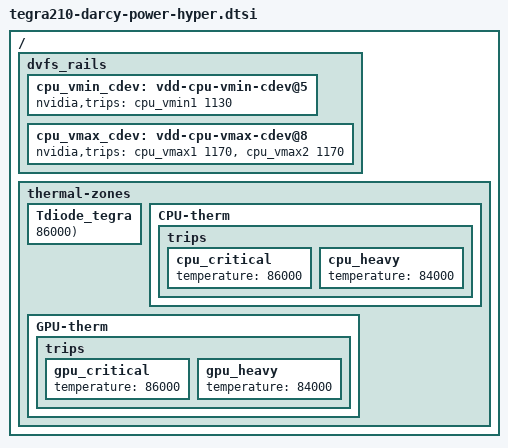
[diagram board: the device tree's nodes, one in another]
/*
 * Copyright (c) 2017, NVIDIA CORPORATION.  All rights reserved.
 *
 * This program is free software; you can redistribute it and/or modify
 * it under the terms of the GNU General Public License as published by
 * the Free Software Foundation; either version 2 of the License, or
 * (at your option) any later version.
 *
 * This program is distributed in the hope that it will be useful, but WITHOUT
 * ANY WARRANTY; without even the implied warranty of MERCHANTABILITY or
 * FITNESS FOR A PARTICULAR PURPOSE.  See the GNU General Public License for
 * more details.
 *
 * You should have received a copy of the GNU General Public License along
 * along with this program. If not, see <http://www.gnu.org/licenses/>.
 */

/ {
	dvfs_rails {
		cpu_vmin_cdev: vdd-cpu-vmin-cdev@5 {
			nvidia,trips = <&cpu_vmin1 1130>;
		};
		cpu_vmax_cdev: vdd-cpu-vmax-cdev@8 {
			nvidia,trips = <&cpu_vmax1 1170 &cpu_vmax2 1170>;
		};
	};
	thermal-zones {
		Tdiode_tegra {
			SET_MAP_TRIP(cpu, cpu, vmin, 1, 86000);
		};
		CPU-therm {
			trips {
				cpu_critical {
					temperature = <86000>;
				};
				cpu_heavy {
					temperature = <84000>;
				};
			};
		};
		GPU-therm {
			trips {
				gpu_critical {
					temperature = <86000>;
				};
				gpu_heavy {
					temperature = <84000>;
				};
			};
		};
	};
};
